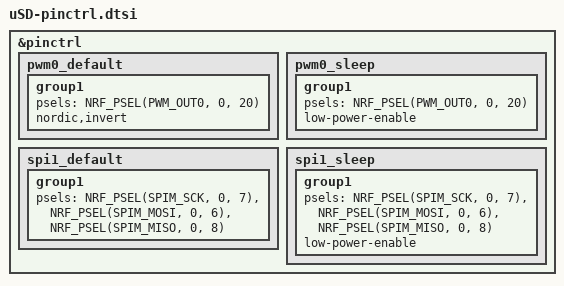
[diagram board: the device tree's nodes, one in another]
/*
 * Copyright (c) 2022 Nordic Semiconductor
 * SPDX-License-Identifier: Apache-2.0
 */

 &pinctrl {

	pwm0_default: pwm0_default {
		group1 {
			psels = <NRF_PSEL(PWM_OUT0, 0, 20)>;
			nordic,invert;
		};
	};

	pwm0_sleep: pwm0_sleep {
		group1 {
			psels = <NRF_PSEL(PWM_OUT0, 0, 20)>;
			low-power-enable;
		};
	};

	spi1_default: spi1_default {
		group1 {
			psels = <NRF_PSEL(SPIM_SCK, 0, 7)>,
				<NRF_PSEL(SPIM_MOSI, 0, 6)>,
				<NRF_PSEL(SPIM_MISO, 0, 8)>;
		};
	};

	spi1_sleep: spi1_sleep {
		group1 {
			psels = <NRF_PSEL(SPIM_SCK, 0, 7)>,
				<NRF_PSEL(SPIM_MOSI, 0, 6)>,
				<NRF_PSEL(SPIM_MISO, 0, 8)>;
			low-power-enable;
		};
	};	
};


